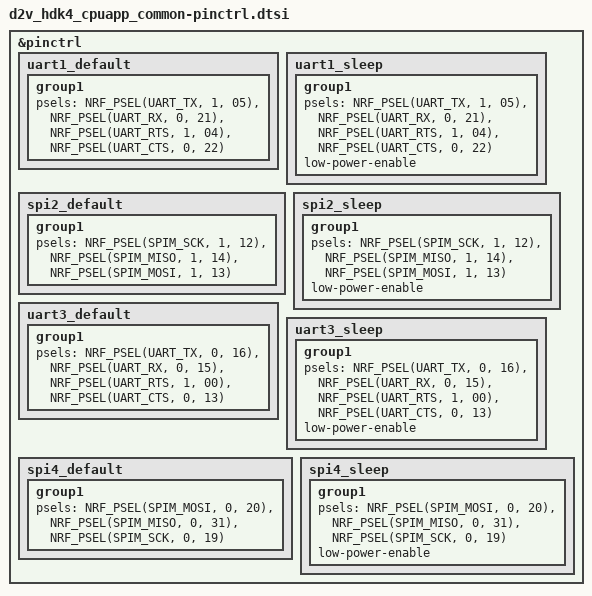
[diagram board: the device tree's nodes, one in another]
/*
 * Copyright (c) 2022 Nordic Semiconductor
 * SPDX-License-Identifier: Apache-2.0
 */

&pinctrl {

	uart1_default: uart1_default {
		group1 {
			psels = <NRF_PSEL(UART_TX, 1, 05)>,
				<NRF_PSEL(UART_RX, 0, 21)>,
				<NRF_PSEL(UART_RTS, 1, 04)>,
				<NRF_PSEL(UART_CTS, 0, 22)>;
		};
	};

	uart1_sleep: uart1_sleep {
		group1 {
			psels = <NRF_PSEL(UART_TX, 1, 05)>,
				<NRF_PSEL(UART_RX, 0, 21)>,
				<NRF_PSEL(UART_RTS, 1, 04)>,
				<NRF_PSEL(UART_CTS, 0, 22)>;
			low-power-enable;
		};
	};

	spi2_default: spi2_default {
		group1 {
			psels = <NRF_PSEL(SPIM_SCK, 1, 12)>,
				<NRF_PSEL(SPIM_MISO, 1, 14)>,
				<NRF_PSEL(SPIM_MOSI, 1, 13)>;
		};
	};

	spi2_sleep: spi2_sleep {
		group1 {
			psels = <NRF_PSEL(SPIM_SCK, 1, 12)>,
				<NRF_PSEL(SPIM_MISO, 1, 14)>,
				<NRF_PSEL(SPIM_MOSI, 1, 13)>;
			low-power-enable;
		};
	};

	uart3_default: uart3_default {
		group1 {
			psels = <NRF_PSEL(UART_TX, 0, 16)>,
				<NRF_PSEL(UART_RX, 0, 15)>,
				<NRF_PSEL(UART_RTS, 1, 00)>,
				<NRF_PSEL(UART_CTS, 0, 13)>;
		};
	};

	uart3_sleep: uart3_sleep {
		group1 {
			psels = <NRF_PSEL(UART_TX, 0, 16)>,
				<NRF_PSEL(UART_RX, 0, 15)>,
				<NRF_PSEL(UART_RTS, 1, 00)>,
				<NRF_PSEL(UART_CTS, 0, 13)>;
			low-power-enable;
		};
	};

	spi4_default: spi4_default {
		group1 {
			psels = <NRF_PSEL(SPIM_MOSI, 0, 20)>,
				<NRF_PSEL(SPIM_MISO, 0, 31)>,
				<NRF_PSEL(SPIM_SCK, 0, 19)>;
		};
	};

	spi4_sleep: spi4_sleep {
		group1 {
			psels = <NRF_PSEL(SPIM_MOSI, 0, 20)>,
				<NRF_PSEL(SPIM_MISO, 0, 31)>,
				<NRF_PSEL(SPIM_SCK, 0, 19)>;
			low-power-enable;
		};
	};
};
